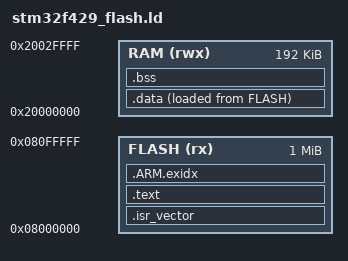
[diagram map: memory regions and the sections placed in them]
ENTRY(Reset_Handler)

MEMORY {
  FLASH (rx)  : ORIGIN = 0x08000000, LENGTH = 1M
  RAM   (rwx) : ORIGIN = 0x20000000, LENGTH = 192K
}

SECTIONS {
  .isr_vector : {
    KEEP(*(.isr_vector))
  } > FLASH

  .text : {
    *(.text*)
    *(.rodata*)
    *(.glue_7*)
    *(.eh_frame*)
  } > FLASH

  .ARM.exidx : {
    *(.ARM.exidx*)
  } > FLASH

  _sidata = LOADADDR(.data);
  .data : {
    _sdata = .;
    *(.data*)
    _edata = .;
  } > RAM AT > FLASH

  .bss (NOLOAD) : {
    _sbss = .;
    *(.bss*)
    *(COMMON)
    _ebss = .;
  } > RAM
}
